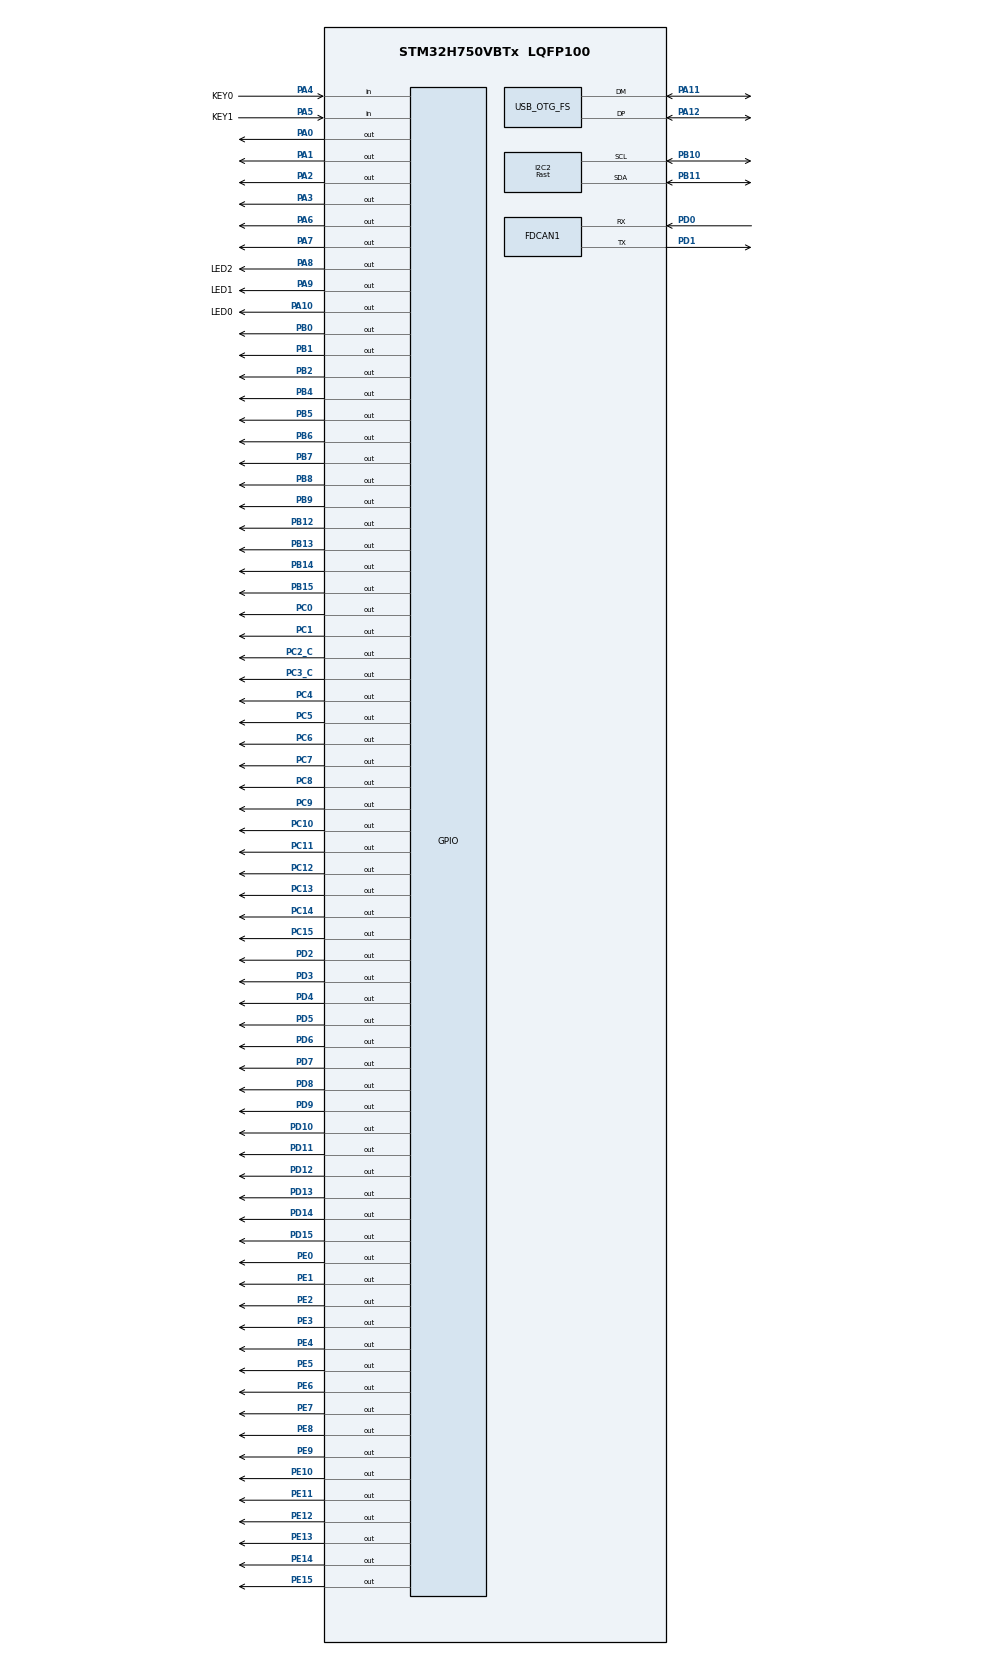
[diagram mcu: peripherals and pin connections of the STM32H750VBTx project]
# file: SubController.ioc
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ADC3.Channel-0\#ChannelRegularConversion=ADC_CHANNEL_TEMPSENSOR
ADC3.Channel-1\#ChannelRegularConversion=ADC_CHANNEL_VREFINT
ADC3.NbrOfConversion=2
ADC3.NbrOfConversionFlag=1
ADC3.OffsetNumber-0\#ChannelRegularConversion=ADC_OFFSET_NONE
ADC3.OffsetNumber-1\#ChannelRegularConversion=ADC_OFFSET_NONE
ADC3.OffsetSignedSaturation-0\#ChannelRegularConversion=DISABLE
ADC3.OffsetSignedSaturation-1\#ChannelRegularConversion=DISABLE
ADC3.Rank-0\#ChannelRegularConversion=1
ADC3.Rank-1\#ChannelRegularConversion=2
ADC3.SamplingTime-0\#ChannelRegularConversion=ADC_SAMPLETIME_810CYCLES_5
ADC3.SamplingTime-1\#ChannelRegularConversion=ADC_SAMPLETIME_810CYCLES_5
CORTEX_M7.BaseAddress_S-Cortex_Memory_Protection_Unit_Region1_Settings_S=0x2400000
CORTEX_M7.CPU_DCache=Disabled
CORTEX_M7.CPU_ICache=Disabled
CORTEX_M7.Enable_S-Cortex_Memory_Protection_Unit_Region1_Settings_S=MPU_REGION_ENABLE
CORTEX_M7.IsCacheable_S-Cortex_Memory_Protection_Unit_Region1_Settings_S=MPU_ACCESS_CACHEABLE
CORTEX_M7.IsShareable_S-Cortex_Memory_Protection_Unit_Region1_Settings_S=MPU_ACCESS_SHAREABLE
CORTEX_M7.MPU_Control=__NULL
CORTEX_M7.Size_S-Cortex_Memory_Protection_Unit_Region1_Settings_S=MPU_REGION_SIZE_512KB
CORTEX_M7.default_mode_Activation=0
Dma.MEMTOMEM.0.Direction=DMA_MEMORY_TO_MEMORY
Dma.MEMTOMEM.0.EventEnable=DISABLE
Dma.MEMTOMEM.0.FIFOMode=DMA_FIFOMODE_ENABLE
Dma.MEMTOMEM.0.FIFOThreshold=DMA_FIFO_THRESHOLD_HALFFULL
Dma.MEMTOMEM.0.Instance=DMA1_Stream0
Dma.MEMTOMEM.0.MemBurst=DMA_MBURST_SINGLE
Dma.MEMTOMEM.0.MemDataAlignment=DMA_MDATAALIGN_HALFWORD
Dma.MEMTOMEM.0.MemInc=DMA_MINC_DISABLE
Dma.MEMTOMEM.0.Mode=DMA_NORMAL
Dma.MEMTOMEM.0.PeriphBurst=DMA_PBURST_SINGLE
Dma.MEMTOMEM.0.PeriphDataAlignment=DMA_PDATAALIGN_HALFWORD
Dma.MEMTOMEM.0.PeriphInc=DMA_PINC_ENABLE
Dma.MEMTOMEM.0.Polarity=HAL_DMAMUX_REQ_GEN_RISING
Dma.MEMTOMEM.0.Priority=DMA_PRIORITY_HIGH
Dma.MEMTOMEM.0.RequestNumber=1
Dma.MEMTOMEM.0.SignalID=NONE
Dma.MEMTOMEM.0.SyncEnable=DISABLE
Dma.MEMTOMEM.0.SyncPolarity=HAL_DMAMUX_SYNC_NO_EVENT
Dma.MEMTOMEM.0.SyncRequestNumber=1
Dma.MEMTOMEM.0.SyncSignalID=NONE
Dma.MEMTOMEM.1.Direction=DMA_MEMORY_TO_MEMORY
Dma.MEMTOMEM.1.EventEnable=DISABLE
Dma.MEMTOMEM.1.FIFOMode=DMA_FIFOMODE_ENABLE
Dma.MEMTOMEM.1.FIFOThreshold=DMA_FIFO_THRESHOLD_HALFFULL
Dma.MEMTOMEM.1.Instance=DMA1_Stream1
Dma.MEMTOMEM.1.MemBurst=DMA_MBURST_SINGLE
Dma.MEMTOMEM.1.MemDataAlignment=DMA_MDATAALIGN_HALFWORD
Dma.MEMTOMEM.1.MemInc=DMA_MINC_DISABLE
Dma.MEMTOMEM.1.Mode=DMA_NORMAL
Dma.MEMTOMEM.1.PeriphBurst=DMA_PBURST_SINGLE
Dma.MEMTOMEM.1.PeriphDataAlignment=DMA_PDATAALIGN_HALFWORD
Dma.MEMTOMEM.1.PeriphInc=DMA_PINC_ENABLE
Dma.MEMTOMEM.1.Polarity=HAL_DMAMUX_REQ_GEN_RISING
Dma.MEMTOMEM.1.Priority=DMA_PRIORITY_HIGH
Dma.MEMTOMEM.1.RequestNumber=1
Dma.MEMTOMEM.1.SignalID=NONE
Dma.MEMTOMEM.1.SyncEnable=DISABLE
Dma.MEMTOMEM.1.SyncPolarity=HAL_DMAMUX_SYNC_NO_EVENT
Dma.MEMTOMEM.1.SyncRequestNumber=1
Dma.MEMTOMEM.1.SyncSignalID=NONE
Dma.MEMTOMEM.2.Direction=DMA_MEMORY_TO_MEMORY
Dma.MEMTOMEM.2.EventEnable=DISABLE
Dma.MEMTOMEM.2.FIFOMode=DMA_FIFOMODE_ENABLE
Dma.MEMTOMEM.2.FIFOThreshold=DMA_FIFO_THRESHOLD_HALFFULL
Dma.MEMTOMEM.2.Instance=DMA1_Stream2
Dma.MEMTOMEM.2.MemBurst=DMA_MBURST_SINGLE
Dma.MEMTOMEM.2.MemDataAlignment=DMA_MDATAALIGN_HALFWORD
Dma.MEMTOMEM.2.MemInc=DMA_MINC_DISABLE
Dma.MEMTOMEM.2.Mode=DMA_NORMAL
Dma.MEMTOMEM.2.PeriphBurst=DMA_PBURST_SINGLE
Dma.MEMTOMEM.2.PeriphDataAlignment=DMA_PDATAALIGN_HALFWORD
Dma.MEMTOMEM.2.PeriphInc=DMA_PINC_ENABLE
Dma.MEMTOMEM.2.Polarity=HAL_DMAMUX_REQ_GEN_RISING
Dma.MEMTOMEM.2.Priority=DMA_PRIORITY_HIGH
Dma.MEMTOMEM.2.RequestNumber=1
Dma.MEMTOMEM.2.SignalID=NONE
Dma.MEMTOMEM.2.SyncEnable=DISABLE
Dma.MEMTOMEM.2.SyncPolarity=HAL_DMAMUX_SYNC_NO_EVENT
Dma.MEMTOMEM.2.SyncRequestNumber=1
Dma.MEMTOMEM.2.SyncSignalID=NONE
Dma.MEMTOMEM.3.Direction=DMA_MEMORY_TO_MEMORY
Dma.MEMTOMEM.3.EventEnable=DISABLE
Dma.MEMTOMEM.3.FIFOMode=DMA_FIFOMODE_ENABLE
Dma.MEMTOMEM.3.FIFOThreshold=DMA_FIFO_THRESHOLD_HALFFULL
Dma.MEMTOMEM.3.Instance=DMA2_Stream0
Dma.MEMTOMEM.3.MemBurst=DMA_MBURST_SINGLE
Dma.MEMTOMEM.3.MemDataAlignment=DMA_MDATAALIGN_HALFWORD
Dma.MEMTOMEM.3.MemInc=DMA_MINC_DISABLE
Dma.MEMTOMEM.3.Mode=DMA_NORMAL
Dma.MEMTOMEM.3.PeriphBurst=DMA_PBURST_SINGLE
Dma.MEMTOMEM.3.PeriphDataAlignment=DMA_PDATAALIGN_HALFWORD
Dma.MEMTOMEM.3.PeriphInc=DMA_PINC_ENABLE
Dma.MEMTOMEM.3.Polarity=HAL_DMAMUX_REQ_GEN_RISING
Dma.MEMTOMEM.3.Priority=DMA_PRIORITY_HIGH
Dma.MEMTOMEM.3.RequestNumber=1
Dma.MEMTOMEM.3.SignalID=NONE
Dma.MEMTOMEM.3.SyncEnable=DISABLE
Dma.MEMTOMEM.3.SyncPolarity=HAL_DMAMUX_SYNC_NO_EVENT
Dma.MEMTOMEM.3.SyncRequestNumber=1
Dma.MEMTOMEM.3.SyncSignalID=NONE
Dma.MEMTOMEM.4.Direction=DMA_MEMORY_TO_MEMORY
Dma.MEMTOMEM.4.EventEnable=DISABLE
Dma.MEMTOMEM.4.FIFOMode=DMA_FIFOMODE_ENABLE
Dma.MEMTOMEM.4.FIFOThreshold=DMA_FIFO_THRESHOLD_HALFFULL
Dma.MEMTOMEM.4.Instance=DMA2_Stream1
Dma.MEMTOMEM.4.MemBurst=DMA_MBURST_SINGLE
Dma.MEMTOMEM.4.MemDataAlignment=DMA_MDATAALIGN_HALFWORD
Dma.MEMTOMEM.4.MemInc=DMA_MINC_DISABLE
Dma.MEMTOMEM.4.Mode=DMA_NORMAL
Dma.MEMTOMEM.4.PeriphBurst=DMA_PBURST_SINGLE
Dma.MEMTOMEM.4.PeriphDataAlignment=DMA_PDATAALIGN_HALFWORD
Dma.MEMTOMEM.4.PeriphInc=DMA_PINC_ENABLE
Dma.MEMTOMEM.4.Polarity=HAL_DMAMUX_REQ_GEN_RISING
Dma.MEMTOMEM.4.Priority=DMA_PRIORITY_HIGH
Dma.MEMTOMEM.4.RequestNumber=1
Dma.MEMTOMEM.4.SignalID=NONE
Dma.MEMTOMEM.4.SyncEnable=DISABLE
Dma.MEMTOMEM.4.SyncPolarity=HAL_DMAMUX_SYNC_NO_EVENT
Dma.MEMTOMEM.4.SyncRequestNumber=1
Dma.MEMTOMEM.4.SyncSignalID=NONE
Dma.MEMTOMEM.5.Direction=DMA_MEMORY_TO_MEMORY
Dma.MEMTOMEM.5.EventEnable=DISABLE
Dma.MEMTOMEM.5.FIFOMode=DMA_FIFOMODE_ENABLE
Dma.MEMTOMEM.5.FIFOThreshold=DMA_FIFO_THRESHOLD_HALFFULL
Dma.MEMTOMEM.5.Instance=DMA2_Stream3
Dma.MEMTOMEM.5.MemBurst=DMA_MBURST_SINGLE
Dma.MEMTOMEM.5.MemDataAlignment=DMA_MDATAALIGN_HALFWORD
Dma.MEMTOMEM.5.MemInc=DMA_MINC_DISABLE
Dma.MEMTOMEM.5.Mode=DMA_NORMAL
Dma.MEMTOMEM.5.PeriphBurst=DMA_PBURST_SINGLE
Dma.MEMTOMEM.5.PeriphDataAlignment=DMA_PDATAALIGN_HALFWORD
Dma.MEMTOMEM.5.PeriphInc=DMA_PINC_ENABLE
Dma.MEMTOMEM.5.Polarity=HAL_DMAMUX_REQ_GEN_RISING
Dma.MEMTOMEM.5.Priority=DMA_PRIORITY_HIGH
Dma.MEMTOMEM.5.RequestNumber=1
Dma.MEMTOMEM.5.SignalID=NONE
Dma.MEMTOMEM.5.SyncEnable=DISABLE
Dma.MEMTOMEM.5.SyncPolarity=HAL_DMAMUX_SYNC_NO_EVENT
Dma.MEMTOMEM.5.SyncRequestNumber=1
Dma.MEMTOMEM.5.SyncSignalID=NONE
Dma.Request0=MEMTOMEM
Dma.Request1=MEMTOMEM
Dma.Request2=MEMTOMEM
Dma.Request3=MEMTOMEM
Dma.Request4=MEMTOMEM
Dma.Request5=MEMTOMEM
FDCAN1.CalculateBaudRateNominal=312500
FDCAN1.CalculateTimeBitNominal=3200
FDCAN1.CalculateTimeQuantumNominal=640.0
I2C2.I2C_Speed_Mode=I2C_Fast
I2C2.Timing=0x009034B6
Mcu.Family=STM32H7
Mcu.Name=STM32H750VBTx
Mcu.Package=LQFP100
NVIC.OTG_FS_IRQn=true\:0\:0\:false\:false\:true\:false\:true\:true
NVIC.PriorityGroup=NVIC_PRIORITYGROUP_4
NVIC.TIM1_UP_IRQn=true\:0\:0\:false\:false\:true\:true\:true\:true
PA0.GPIO_Speed=GPIO_SPEED_FREQ_VERY_HIGH
PA0.Signal=GPIO_Output
PA1.GPIO_Speed=GPIO_SPEED_FREQ_VERY_HIGH
PA1.Signal=GPIO_Output
PA10.GPIO_Label=LED0
PA10.Signal=GPIO_Output
PA11.Mode=Device_Only
PA11.Signal=USB_OTG_FS_DM
PA12.Mode=Device_Only
PA12.Signal=USB_OTG_FS_DP
PA13\ (JTMS/SWDIO).Mode=JTAG_4_pins
PA13\ (JTMS/SWDIO).Signal=DEBUG_JTMS-SWDIO
PA14\ (JTCK/SWCLK).Mode=JTAG_4_pins
PA14\ (JTCK/SWCLK).Signal=DEBUG_JTCK-SWCLK
PA15\ (JTDI).Mode=JTAG_4_pins
PA15\ (JTDI).Signal=DEBUG_JTDI
PA2.GPIO_Speed=GPIO_SPEED_FREQ_VERY_HIGH
PA2.Signal=GPIO_Output
PA3.GPIO_Speed=GPIO_SPEED_FREQ_VERY_HIGH
PA3.Signal=GPIO_Output
PA4.GPIO_Label=KEY0
PA4.Signal=GPIO_Input
PA5.GPIO_Label=KEY1
PA5.Signal=GPIO_Input
PA6.GPIO_Speed=GPIO_SPEED_FREQ_VERY_HIGH
PA6.Signal=GPIO_Output
PA7.GPIO_Speed=GPIO_SPEED_FREQ_VERY_HIGH
PA7.Signal=GPIO_Output
PA8.GPIO_Label=LED2
PA8.Signal=GPIO_Output
PA9.GPIO_Label=LED1
PA9.Signal=GPIO_Output
PB0.GPIO_Speed=GPIO_SPEED_FREQ_VERY_HIGH
PB0.Signal=GPIO_Output
PB1.GPIO_Speed=GPIO_SPEED_FREQ_VERY_HIGH
PB1.Signal=GPIO_Output
PB10.Mode=I2C
PB10.Signal=I2C2_SCL
PB11.Mode=I2C
PB11.Signal=I2C2_SDA
PB12.GPIO_Speed=GPIO_SPEED_FREQ_VERY_HIGH
PB12.Signal=GPIO_Output
PB13.GPIO_Speed=GPIO_SPEED_FREQ_VERY_HIGH
PB13.Signal=GPIO_Output
PB14.GPIO_Speed=GPIO_SPEED_FREQ_VERY_HIGH
PB14.Signal=GPIO_Output
PB15.GPIO_Speed=GPIO_SPEED_FREQ_VERY_HIGH
PB15.Signal=GPIO_Output
PB2.GPIO_Speed=GPIO_SPEED_FREQ_VERY_HIGH
PB2.Signal=GPIO_Output
PB3\ (JTDO/TRACESWO).Mode=JTAG_4_pins
PB3\ (JTDO/TRACESWO).Signal=DEBUG_JTDO-SWO
PB4\ (NJTRST).GPIO_Speed=GPIO_SPEED_FREQ_VERY_HIGH
PB4\ (NJTRST).Signal=GPIO_Output
PB5.GPIO_Speed=GPIO_SPEED_FREQ_VERY_HIGH
PB5.Signal=GPIO_Output
PB6.GPIO_Speed=GPIO_SPEED_FREQ_VERY_HIGH
PB6.Signal=GPIO_Output
PB7.GPIO_Speed=GPIO_SPEED_FREQ_VERY_HIGH
PB7.Signal=GPIO_Output
PB8.GPIO_Speed=GPIO_SPEED_FREQ_VERY_HIGH
PB8.Signal=GPIO_Output
PB9.GPIO_Speed=GPIO_SPEED_FREQ_VERY_HIGH
PB9.Signal=GPIO_Output
PC0.GPIO_Speed=GPIO_SPEED_FREQ_VERY_HIGH
PC0.Signal=GPIO_Output
PC1.GPIO_Speed=GPIO_SPEED_FREQ_VERY_HIGH
PC1.Signal=GPIO_Output
PC10.GPIO_Speed=GPIO_SPEED_FREQ_VERY_HIGH
PC10.Signal=GPIO_Output
PC11.GPIO_Speed=GPIO_SPEED_FREQ_VERY_HIGH
PC11.Signal=GPIO_Output
PC12.GPIO_Speed=GPIO_SPEED_FREQ_VERY_HIGH
PC12.Signal=GPIO_Output
PC13.GPIO_Speed=GPIO_SPEED_FREQ_LOW
PC13.Signal=GPIO_Output
PC14-OSC32_IN\ (OSC32_IN).GPIO_Speed=GPIO_SPEED_FREQ_LOW
PC14-OSC32_IN\ (OSC32_IN).Signal=GPIO_Output
PC15-OSC32_OUT\ (OSC32_OUT).GPIO_Speed=GPIO_SPEED_FREQ_LOW
PC15-OSC32_OUT\ (OSC32_OUT).Signal=GPIO_Output
PC2_C.GPIO_Speed=GPIO_SPEED_FREQ_VERY_HIGH
PC2_C.Signal=GPIO_Output
PC3_C.GPIO_Speed=GPIO_SPEED_FREQ_VERY_HIGH
PC3_C.Signal=GPIO_Output
PC4.GPIO_Speed=GPIO_SPEED_FREQ_VERY_HIGH
PC4.Signal=GPIO_Output
PC5.GPIO_Speed=GPIO_SPEED_FREQ_VERY_HIGH
PC5.Signal=GPIO_Output
PC6.GPIO_Speed=GPIO_SPEED_FREQ_VERY_HIGH
PC6.Signal=GPIO_Output
PC7.GPIO_Speed=GPIO_SPEED_FREQ_VERY_HIGH
PC7.Signal=GPIO_Output
PC8.GPIO_Speed=GPIO_SPEED_FREQ_VERY_HIGH
PC8.Signal=GPIO_Output
PC9.GPIO_Speed=GPIO_SPEED_FREQ_VERY_HIGH
PC9.Signal=GPIO_Output
PD0.Mode=FDCAN_Activate
PD0.Signal=FDCAN1_RX
PD1.Mode=FDCAN_Activate
PD1.Signal=FDCAN1_TX
PD10.GPIO_Speed=GPIO_SPEED_FREQ_VERY_HIGH
PD10.Signal=GPIO_Output
PD11.GPIO_Speed=GPIO_SPEED_FREQ_VERY_HIGH
PD11.Signal=GPIO_Output
PD12.GPIO_Speed=GPIO_SPEED_FREQ_VERY_HIGH
PD12.Signal=GPIO_Output
PD13.GPIO_Speed=GPIO_SPEED_FREQ_VERY_HIGH
PD13.Signal=GPIO_Output
PD14.GPIO_Speed=GPIO_SPEED_FREQ_VERY_HIGH
PD14.Signal=GPIO_Output
PD15.GPIO_Speed=GPIO_SPEED_FREQ_VERY_HIGH
PD15.Signal=GPIO_Output
PD2.GPIO_Speed=GPIO_SPEED_FREQ_VERY_HIGH
PD2.Signal=GPIO_Output
PD3.GPIO_Speed=GPIO_SPEED_FREQ_VERY_HIGH
PD3.Signal=GPIO_Output
PD4.GPIO_Speed=GPIO_SPEED_FREQ_VERY_HIGH
PD4.Signal=GPIO_Output
PD5.GPIO_Speed=GPIO_SPEED_FREQ_VERY_HIGH
PD5.Signal=GPIO_Output
PD6.GPIO_Speed=GPIO_SPEED_FREQ_VERY_HIGH
PD6.Signal=GPIO_Output
PD7.GPIO_Speed=GPIO_SPEED_FREQ_VERY_HIGH
PD7.Signal=GPIO_Output
PD8.GPIO_Speed=GPIO_SPEED_FREQ_VERY_HIGH
PD8.Signal=GPIO_Output
PD9.GPIO_Speed=GPIO_SPEED_FREQ_VERY_HIGH
PD9.Signal=GPIO_Output
PE0.GPIO_Speed=GPIO_SPEED_FREQ_VERY_HIGH
PE0.Signal=GPIO_Output
PE1.GPIO_Speed=GPIO_SPEED_FREQ_VERY_HIGH
PE1.Signal=GPIO_Output
PE10.GPIO_Speed=GPIO_SPEED_FREQ_VERY_HIGH
PE10.Signal=GPIO_Output
PE11.GPIO_Speed=GPIO_SPEED_FREQ_VERY_HIGH
PE11.Signal=GPIO_Output
PE12.GPIO_Speed=GPIO_SPEED_FREQ_VERY_HIGH
PE12.Signal=GPIO_Output
PE13.GPIO_Speed=GPIO_SPEED_FREQ_VERY_HIGH
PE13.Signal=GPIO_Output
PE14.GPIO_Speed=GPIO_SPEED_FREQ_VERY_HIGH
PE14.Signal=GPIO_Output
PE15.GPIO_Speed=GPIO_SPEED_FREQ_VERY_HIGH
PE15.Signal=GPIO_Output
PE2.GPIO_Speed=GPIO_SPEED_FREQ_VERY_HIGH
PE2.Signal=GPIO_Output
PE3.GPIO_Speed=GPIO_SPEED_FREQ_VERY_HIGH
PE3.Signal=GPIO_Output
PE4.GPIO_Speed=GPIO_SPEED_FREQ_VERY_HIGH
PE4.Signal=GPIO_Output
PE5.GPIO_Speed=GPIO_SPEED_FREQ_VERY_HIGH
PE5.Signal=GPIO_Output
PE6.GPIO_Speed=GPIO_SPEED_FREQ_VERY_HIGH
PE6.Signal=GPIO_Output
PE7.GPIO_Speed=GPIO_SPEED_FREQ_VERY_HIGH
PE7.Signal=GPIO_Output
PE8.GPIO_Speed=GPIO_SPEED_FREQ_VERY_HIGH
PE8.Signal=GPIO_Output
PE9.GPIO_Speed=GPIO_SPEED_FREQ_VERY_HIGH
PE9.Signal=GPIO_Output
PH0-OSC_IN\ (PH0).Mode=HSE-External-Oscillator
PH0-OSC_IN\ (PH0).Signal=RCC_OSC_IN
PH1-OSC_OUT\ (PH1).Mode=HSE-External-Oscillator
PH1-OSC_OUT\ (PH1).Signal=RCC_OSC_OUT
ProjectManager.HeapSize=0x200
ProjectManager.StackSize=0x400
ProjectManager.TargetToolchain=Makefile
RCC.ADCCLockSelection=RCC_ADCCLKSOURCE_CLKP
RCC.ADCFreq_Value=64000000
RCC.APB1Freq_Value=100000000
RCC.APB2Freq_Value=100000000
RCC.APB3Freq_Value=100000000
RCC.APB4Freq_Value=100000000
RCC.CortexFreq_Value=400000000
RCC.D1PPRE=RCC_APB3_DIV2
RCC.D2PPRE1=RCC_APB1_DIV2
RCC.D2PPRE2=RCC_APB2_DIV2
RCC.D3PPRE=RCC_APB4_DIV2
RCC.DIVM1=2
RCC.DIVM2=10
RCC.DIVN1=64
RCC.DIVN2=100
RCC.DIVQ1=13
RCC.FDCANCLockSelection=RCC_FDCANCLKSOURCE_HSE
RCC.HCLKFreq_Value=200000000
RCC.HPRE=RCC_HCLK_DIV2
RCC.HSE_VALUE=25000000
RCC.PLLSourceVirtual=RCC_PLLSOURCE_HSE
RCC.SYSCLKFreq_VALUE=400000000
RCC.SYSCLKSource=RCC_SYSCLKSOURCE_PLLCLK
RCC.USBCLockSelection=RCC_USBCLKSOURCE_HSI48
RCC.USBFreq_Value=48000000
TIM1.AutoReloadPreload=TIM_AUTORELOAD_PRELOAD_ENABLE
TIM1.Period=1000
TIM1.Prescaler=1000
USB_DEVICE.CLASS_NAME_FS=CDC
USB_DEVICE.USBD_LPM_ENABLED-CDC_FS=0
USB_DEVICE.VirtualMode-CDC_FS=Cdc
USB_DEVICE.VirtualModeFS=Cdc_FS
USB_OTG_FS.VirtualMode=Device_Only
VP_ADC3_TempSens_Input.Mode=IN-TempSens
VP_ADC3_Vref_Input.Mode=IN-Vrefint
VP_TIM1_VS_ClockSourceINT.Mode=Internal
VP_USB_DEVICE_VS_USB_DEVICE_CDC_FS.Mode=CDC_FS
board=custom

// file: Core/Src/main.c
/* USER CODE BEGIN Header */
/**
 ******************************************************************************
 * @file           : main.c
 * @brief          : Main program body
 ******************************************************************************
 * @attention
 *
 * Copyright (c) 2024 STMicroelectronics.
 * All rights reserved.
 *
 * This software is licensed under terms that can be found in the LICENSE file
 * in the root directory of this software component.
 * If no LICENSE file comes with this software, it is provided AS-IS.
 *
 ******************************************************************************
 */
/* USER CODE END Header */
#include "main.h"
#include "usb_device.h"

/* USER CODE BEGIN Includes */

#include "dma_manager.h"
#include "transducer.h"
#include "simulation.h"
#include "calibration.h"
#include "custom_math.h"
#include "utiles.h"
#include "communication.h"

/* USER CODE END Includes */

ADC_HandleTypeDef hadc3;

FDCAN_HandleTypeDef hfdcan1;

I2C_HandleTypeDef hi2c2;

TIM_HandleTypeDef htim1;

DMA_HandleTypeDef hdma_memtomem_dma1_stream0;
DMA_HandleTypeDef hdma_memtomem_dma1_stream1;
DMA_HandleTypeDef hdma_memtomem_dma1_stream2;
DMA_HandleTypeDef hdma_memtomem_dma2_stream0;
DMA_HandleTypeDef hdma_memtomem_dma2_stream1;
DMA_HandleTypeDef hdma_memtomem_dma2_stream3;
/* USER CODE BEGIN PV */

DMA_HandleTypeDef hdma_memtomem_dma1_stream0;
DMA_HandleTypeDef hdma_memtomem_dma1_stream1;
DMA_HandleTypeDef hdma_memtomem_dma1_stream2;
DMA_HandleTypeDef hdma_memtomem_dma2_stream0;
DMA_HandleTypeDef hdma_memtomem_dma2_stream1;
DMA_HandleTypeDef hdma_memtomem_dma2_stream3;

/* USER CODE END PV */

void SystemClock_Config(void);
void PeriphCommonClock_Config(void);
static void MX_GPIO_Init(void);
static void MX_DMA_Init(void);
static void MX_I2C2_Init(void);
static void MX_FDCAN1_Init(void);
static void MX_TIM1_Init(void);
static void MX_ADC3_Init(void);

int main(void)
{

  /* MCU Configuration--------------------------------------------------------*/

  /* Reset of all peripherals, Initializes the Flash interface and the Systick. */
  HAL_Init();

  /* USER CODE BEGIN Init */

  static uint32_t loop_count = 0;
  static uint32_t last_check_tick = 0;

  /* USER CODE END Init */

  /* Configure the system clock */
  SystemClock_Config();

/* Configure the peripherals common clocks */
  PeriphCommonClock_Config();

  /* Initialize all configured peripherals */
  MX_GPIO_Init();
  MX_DMA_Init();
  MX_I2C2_Init();
  MX_USB_DEVICE_Init();
  MX_FDCAN1_Init();
  MX_TIM1_Init();
  MX_ADC3_Init();
  /* USER CODE BEGIN 2 */

  Comm_Init();
  Init_DWT();
  Transducer_Init();
  DMA_Init();

  /* USER CODE END 2 */

  /* Infinite loop */
  /* USER CODE BEGIN WHILE */

  while (1)
  {
    loop_count++;
    if (HAL_GetTick() - last_check_tick >= 1000)
    {
      System_Loop_Freq = (float)loop_count;
      loop_count = 0;
      last_check_tick = HAL_GetTick();
    }

    sysTickDelta = SysTick->VAL;

    LED_Indicate_Blink();

    // Calibration Mode Switch
    Switch_Calibration_Mode();

    // Simulation Mode Switch
    Switch_Simulation_Mode();

    Apply_Vibration();

    /* USER CODE END WHILE */

  }
}

void SystemClock_Config(void)
{
  RCC_OscInitTypeDef RCC_OscInitStruct = {0};
  RCC_ClkInitTypeDef RCC_ClkInitStruct = {0};

  /** Supply configuration update enable
  */
  HAL_PWREx_ConfigSupply(PWR_LDO_SUPPLY);

  /** Configure the main internal regulator output voltage
  */
  __HAL_PWR_VOLTAGESCALING_CONFIG(PWR_REGULATOR_VOLTAGE_SCALE1);

  while(!__HAL_PWR_GET_FLAG(PWR_FLAG_VOSRDY)) {}

  /** Initializes the RCC Oscillators according to the specified parameters
  * in the RCC_OscInitTypeDef structure.
  */
  RCC_OscInitStruct.OscillatorType = RCC_OSCILLATORTYPE_HSI48|RCC_OSCILLATORTYPE_HSI
                              |RCC_OSCILLATORTYPE_HSE;
  RCC_OscInitStruct.HSEState = RCC_HSE_ON;
  RCC_OscInitStruct.HSIState = RCC_HSI_DIV1;
  RCC_OscInitStruct.HSICalibrationValue = RCC_HSICALIBRATION_DEFAULT;
  RCC_OscInitStruct.HSI48State = RCC_HSI48_ON;
  RCC_OscInitStruct.PLL.PLLState = RCC_PLL_ON;
  RCC_OscInitStruct.PLL.PLLSource = RCC_PLLSOURCE_HSE;
  RCC_OscInitStruct.PLL.PLLM = 2;
  RCC_OscInitStruct.PLL.PLLN = 64;
  RCC_OscInitStruct.PLL.PLLP = 2;
  RCC_OscInitStruct.PLL.PLLQ = 13;
  RCC_OscInitStruct.PLL.PLLR = 2;
  RCC_OscInitStruct.PLL.PLLRGE = RCC_PLL1VCIRANGE_3;
  RCC_OscInitStruct.PLL.PLLVCOSEL = RCC_PLL1VCOWIDE;
  RCC_OscInitStruct.PLL.PLLFRACN = 0;
  if (HAL_RCC_OscConfig(&RCC_OscInitStruct) != HAL_OK)
  {
    Error_Handler();
  }

  /** Initializes the CPU, AHB and APB buses clocks
  */
  RCC_ClkInitStruct.ClockType = RCC_CLOCKTYPE_HCLK|RCC_CLOCKTYPE_SYSCLK
                              |RCC_CLOCKTYPE_PCLK1|RCC_CLOCKTYPE_PCLK2
                              |RCC_CLOCKTYPE_D3PCLK1|RCC_CLOCKTYPE_D1PCLK1;
  RCC_ClkInitStruct.SYSCLKSource = RCC_SYSCLKSOURCE_PLLCLK;
  RCC_ClkInitStruct.SYSCLKDivider = RCC_SYSCLK_DIV1;
  RCC_ClkInitStruct.AHBCLKDivider = RCC_HCLK_DIV2;
  RCC_ClkInitStruct.APB3CLKDivider = RCC_APB3_DIV2;
  RCC_ClkInitStruct.APB1CLKDivider = RCC_APB1_DIV2;
  RCC_ClkInitStruct.APB2CLKDivider = RCC_APB2_DIV2;
  RCC_ClkInitStruct.APB4CLKDivider = RCC_APB4_DIV2;

  if (HAL_RCC_ClockConfig(&RCC_ClkInitStruct, FLASH_LATENCY_2) != HAL_OK)
  {
    Error_Handler();
  }
}

void PeriphCommonClock_Config(void)
{
  RCC_PeriphCLKInitTypeDef PeriphClkInitStruct = {0};

  /** Initializes the peripherals clock
  */
  PeriphClkInitStruct.PeriphClockSelection = RCC_PERIPHCLK_CKPER;
  PeriphClkInitStruct.CkperClockSelection = RCC_CLKPSOURCE_HSI;
  if (HAL_RCCEx_PeriphCLKConfig(&PeriphClkInitStruct) != HAL_OK)
  {
    Error_Handler();
  }
}

static void MX_ADC3_Init(void)
{

  ADC_ChannelConfTypeDef sConfig = {0};

  /** Common config
  */
  hadc3.Instance = ADC3;
  hadc3.Init.Resolution = ADC_RESOLUTION_16B;
  hadc3.Init.ScanConvMode = ADC_SCAN_ENABLE;
  hadc3.Init.EOCSelection = ADC_EOC_SINGLE_CONV;
  hadc3.Init.LowPowerAutoWait = DISABLE;
  hadc3.Init.ContinuousConvMode = DISABLE;
  hadc3.Init.NbrOfConversion = 2;
  hadc3.Init.DiscontinuousConvMode = DISABLE;
  hadc3.Init.ExternalTrigConv = ADC_SOFTWARE_START;
  hadc3.Init.ExternalTrigConvEdge = ADC_EXTERNALTRIGCONVEDGE_NONE;
  hadc3.Init.ConversionDataManagement = ADC_CONVERSIONDATA_DR;
  hadc3.Init.Overrun = ADC_OVR_DATA_PRESERVED;
  hadc3.Init.LeftBitShift = ADC_LEFTBITSHIFT_NONE;
  hadc3.Init.OversamplingMode = DISABLE;
  if (HAL_ADC_Init(&hadc3) != HAL_OK)
  {
    Error_Handler();
  }

  /** Configure Regular Channel
  */
  sConfig.Channel = ADC_CHANNEL_TEMPSENSOR;
  sConfig.Rank = ADC_REGULAR_RANK_1;
  sConfig.SamplingTime = ADC_SAMPLETIME_810CYCLES_5;
  sConfig.SingleDiff = ADC_SINGLE_ENDED;
  sConfig.OffsetNumber = ADC_OFFSET_NONE;
  sConfig.Offset = 0;
  sConfig.OffsetSignedSaturation = DISABLE;
  if (HAL_ADC_ConfigChannel(&hadc3, &sConfig) != HAL_OK)
  {
    Error_Handler();
  }

  /** Configure Regular Channel
  */
  sConfig.Channel = ADC_CHANNEL_VREFINT;
  sConfig.Rank = ADC_REGULAR_RANK_2;
  if (HAL_ADC_ConfigChannel(&hadc3, &sConfig) != HAL_OK)
  {
    Error_Handler();
  }

}

static void MX_FDCAN1_Init(void)
{

  hfdcan1.Instance = FDCAN1;
  hfdcan1.Init.FrameFormat = FDCAN_FRAME_CLASSIC;
  hfdcan1.Init.Mode = FDCAN_MODE_NORMAL;
  hfdcan1.Init.AutoRetransmission = DISABLE;
  hfdcan1.Init.TransmitPause = DISABLE;
  hfdcan1.Init.ProtocolException = DISABLE;
  hfdcan1.Init.NominalPrescaler = 16;
  hfdcan1.Init.NominalSyncJumpWidth = 1;
  hfdcan1.Init.NominalTimeSeg1 = 2;
  hfdcan1.Init.NominalTimeSeg2 = 2;
  hfdcan1.Init.DataPrescaler = 1;
  hfdcan1.Init.DataSyncJumpWidth = 1;
  hfdcan1.Init.DataTimeSeg1 = 1;
  hfdcan1.Init.DataTimeSeg2 = 1;
  hfdcan1.Init.MessageRAMOffset = 0;
  hfdcan1.Init.StdFiltersNbr = 0;
  hfdcan1.Init.ExtFiltersNbr = 0;
  hfdcan1.Init.RxFifo0ElmtsNbr = 0;
  hfdcan1.Init.RxFifo0ElmtSize = FDCAN_DATA_BYTES_8;
  hfdcan1.Init.RxFifo1ElmtsNbr = 0;
  hfdcan1.Init.RxFifo1ElmtSize = FDCAN_DATA_BYTES_8;
  hfdcan1.Init.RxBuffersNbr = 0;
  hfdcan1.Init.RxBufferSize = FDCAN_DATA_BYTES_8;
  hfdcan1.Init.TxEventsNbr = 0;
  hfdcan1.Init.TxBuffersNbr = 0;
  hfdcan1.Init.TxFifoQueueElmtsNbr = 0;
  hfdcan1.Init.TxFifoQueueMode = FDCAN_TX_FIFO_OPERATION;
  hfdcan1.Init.TxElmtSize = FDCAN_DATA_BYTES_8;
  if (HAL_FDCAN_Init(&hfdcan1) != HAL_OK)
  {
    Error_Handler();
  }

}

static void MX_I2C2_Init(void)
{

  hi2c2.Instance = I2C2;
  hi2c2.Init.Timing = 0x009034B6;
  hi2c2.Init.OwnAddress1 = 0;
  hi2c2.Init.AddressingMode = I2C_ADDRESSINGMODE_7BIT;
  hi2c2.Init.DualAddressMode = I2C_DUALADDRESS_DISABLE;
  hi2c2.Init.OwnAddress2 = 0;
  hi2c2.Init.OwnAddress2Masks = I2C_OA2_NOMASK;
  hi2c2.Init.GeneralCallMode = I2C_GENERALCALL_DISABLE;
  hi2c2.Init.NoStretchMode = I2C_NOSTRETCH_DISABLE;
  if (HAL_I2C_Init(&hi2c2) != HAL_OK)
  {
    Error_Handler();
  }

  /** Configure Analogue filter
  */
  if (HAL_I2CEx_ConfigAnalogFilter(&hi2c2, I2C_ANALOGFILTER_ENABLE) != HAL_OK)
  {
    Error_Handler();
  }

  /** Configure Digital filter
  */
  if (HAL_I2CEx_ConfigDigitalFilter(&hi2c2, 0) != HAL_OK)
  {
    Error_Handler();
  }

}

static void MX_TIM1_Init(void)
{

  TIM_ClockConfigTypeDef sClockSourceConfig = {0};
  TIM_MasterConfigTypeDef sMasterConfig = {0};

  htim1.Instance = TIM1;
  htim1.Init.Prescaler = 1000;
  htim1.Init.CounterMode = TIM_COUNTERMODE_UP;
  htim1.Init.Period = 1000;
  htim1.Init.ClockDivision = TIM_CLOCKDIVISION_DIV1;
  htim1.Init.RepetitionCounter = 0;
  htim1.Init.AutoReloadPreload = TIM_AUTORELOAD_PRELOAD_ENABLE;
  if (HAL_TIM_Base_Init(&htim1) != HAL_OK)
  {
    Error_Handler();
  }
  sClockSourceConfig.ClockSource = TIM_CLOCKSOURCE_INTERNAL;
  if (HAL_TIM_ConfigClockSource(&htim1, &sClockSourceConfig) != HAL_OK)
  {
    Error_Handler();
  }
  sMasterConfig.MasterOutputTrigger = TIM_TRGO_RESET;
  sMasterConfig.MasterOutputTrigger2 = TIM_TRGO2_RESET;
  sMasterConfig.MasterSlaveMode = TIM_MASTERSLAVEMODE_DISABLE;
  if (HAL_TIMEx_MasterConfigSynchronization(&htim1, &sMasterConfig) != HAL_OK)
  {
    Error_Handler();
  }
  /* USER CODE BEGIN TIM1_Init 2 */
  __HAL_FREEZE_TIM1_DBGMCU();
  /* USER CODE END TIM1_Init 2 */

}

static void MX_DMA_Init(void)
{

  /* DMA controller clock enable */
  __HAL_RCC_DMA1_CLK_ENABLE();
  __HAL_RCC_DMA2_CLK_ENABLE();

  /* Configure DMA request hdma_memtomem_dma1_stream0 on DMA1_Stream0 */
  hdma_memtomem_dma1_stream0.Instance = DMA1_Stream0;
  hdma_memtomem_dma1_stream0.Init.Request = DMA_REQUEST_MEM2MEM;
  hdma_memtomem_dma1_stream0.Init.Direction = DMA_MEMORY_TO_MEMORY;
  hdma_memtomem_dma1_stream0.Init.PeriphInc = DMA_PINC_ENABLE;
  hdma_memtomem_dma1_stream0.Init.MemInc = DMA_MINC_DISABLE;
  hdma_memtomem_dma1_stream0.Init.PeriphDataAlignment = DMA_PDATAALIGN_HALFWORD;
  hdma_memtomem_dma1_stream0.Init.MemDataAlignment = DMA_MDATAALIGN_HALFWORD;
  hdma_memtomem_dma1_stream0.Init.Mode = DMA_CIRCULAR;
  hdma_memtomem_dma1_stream0.Init.Priority = DMA_PRIORITY_HIGH;
  hdma_memtomem_dma1_stream0.Init.FIFOMode = DMA_FIFOMODE_DISABLE;
  hdma_memtomem_dma1_stream0.Init.FIFOThreshold = DMA_FIFO_THRESHOLD_HALFFULL;
  hdma_memtomem_dma1_stream0.Init.MemBurst = DMA_MBURST_SINGLE;
  hdma_memtomem_dma1_stream0.Init.PeriphBurst = DMA_PBURST_SINGLE;
  if (HAL_DMA_Init(&hdma_memtomem_dma1_stream0) != HAL_OK)
  {
    Error_Handler( );
  }

  /* Configure DMA request hdma_memtomem_dma1_stream1 on DMA1_Stream1 */
  hdma_memtomem_dma1_stream1.Instance = DMA1_Stream1;
  hdma_memtomem_dma1_stream1.Init.Request = DMA_REQUEST_MEM2MEM;
  hdma_memtomem_dma1_stream1.Init.Direction = DMA_MEMORY_TO_MEMORY;
  hdma_memtomem_dma1_stream1.Init.PeriphInc = DMA_PINC_ENABLE;
  hdma_memtomem_dma1_stream1.Init.MemInc = DMA_MINC_DISABLE;
  hdma_memtomem_dma1_stream1.Init.PeriphDataAlignment = DMA_PDATAALIGN_HALFWORD;
  hdma_memtomem_dma1_stream1.Init.MemDataAlignment = DMA_MDATAALIGN_HALFWORD;
  hdma_memtomem_dma1_stream1.Init.Mode = DMA_CIRCULAR;
  hdma_memtomem_dma1_stream1.Init.Priority = DMA_PRIORITY_HIGH;
  hdma_memtomem_dma1_stream1.Init.FIFOMode = DMA_FIFOMODE_DISABLE;
  hdma_memtomem_dma1_stream1.Init.FIFOThreshold = DMA_FIFO_THRESHOLD_HALFFULL;
  hdma_memtomem_dma1_stream1.Init.MemBurst = DMA_MBURST_SINGLE;
  hdma_memtomem_dma1_stream1.Init.PeriphBurst = DMA_PBURST_SINGLE;
  if (HAL_DMA_Init(&hdma_memtomem_dma1_stream1) != HAL_OK)
  {
    Error_Handler( );
  }

  /* Configure DMA request hdma_memtomem_dma1_stream2 on DMA1_Stream2 */
  hdma_memtomem_dma1_stream2.Instance = DMA1_Stream2;
  hdma_memtomem_dma1_stream2.Init.Request = DMA_REQUEST_MEM2MEM;
  hdma_memtomem_dma1_stream2.Init.Direction = DMA_MEMORY_TO_MEMORY;
  hdma_memtomem_dma1_stream2.Init.PeriphInc = DMA_PINC_ENABLE;
  hdma_memtomem_dma1_stream2.Init.MemInc = DMA_MINC_DISABLE;
  hdma_memtomem_dma1_stream2.Init.PeriphDataAlignment = DMA_PDATAALIGN_HALFWORD;
  hdma_memtomem_dma1_stream2.Init.MemDataAlignment = DMA_MDATAALIGN_HALFWORD;
  hdma_memtomem_dma1_stream2.Init.Mode = DMA_CIRCULAR;
  hdma_memtomem_dma1_stream2.Init.Priority = DMA_PRIORITY_HIGH;
  hdma_memtomem_dma1_stream2.Init.FIFOMode = DMA_FIFOMODE_DISABLE;
  hdma_memtomem_dma1_stream2.Init.FIFOThreshold = DMA_FIFO_THRESHOLD_HALFFULL;
  hdma_memtomem_dma1_stream2.Init.MemBurst = DMA_MBURST_SINGLE;
  hdma_memtomem_dma1_stream2.Init.PeriphBurst = DMA_PBURST_SINGLE;
  if (HAL_DMA_Init(&hdma_memtomem_dma1_stream2) != HAL_OK)
  {
    Error_Handler( );
  }

  /* Configure DMA request hdma_memtomem_dma2_stream0 on DMA2_Stream0 */
  hdma_memtomem_dma2_stream0.Instance = DMA2_Stream0;
  hdma_memtomem_dma2_stream0.Init.Request = DMA_REQUEST_MEM2MEM;
  hdma_memtomem_dma2_stream0.Init.Direction = DMA_MEMORY_TO_MEMORY;
  hdma_memtomem_dma2_stream0.Init.PeriphInc = DMA_PINC_ENABLE;
  hdma_memtomem_dma2_stream0.Init.MemInc = DMA_MINC_DISABLE;
  hdma_memtomem_dma2_stream0.Init.PeriphDataAlignment = DMA_PDATAALIGN_HALFWORD;
  hdma_memtomem_dma2_stream0.Init.MemDataAlignment = DMA_MDATAALIGN_HALFWORD;
  hdma_memtomem_dma2_stream0.Init.Mode = DMA_CIRCULAR;
  hdma_memtomem_dma2_stream0.Init.Priority = DMA_PRIORITY_HIGH;
  hdma_memtomem_dma2_stream0.Init.FIFOMode = DMA_FIFOMODE_DISABLE;
  hdma_memtomem_dma2_stream0.Init.FIFOThreshold = DMA_FIFO_THRESHOLD_HALFFULL;
  hdma_memtomem_dma2_stream0.Init.MemBurst = DMA_MBURST_SINGLE;
  hdma_memtomem_dma2_stream0.Init.PeriphBurst = DMA_PBURST_SINGLE;
  if (HAL_DMA_Init(&hdma_memtomem_dma2_stream0) != HAL_OK)
  {
    Error_Handler( );
  }

  /* Configure DMA request hdma_memtomem_dma2_stream1 on DMA2_Stream1 */
  hdma_memtomem_dma2_stream1.Instance = DMA2_Stream1;
  hdma_memtomem_dma2_stream1.Init.Request = DMA_REQUEST_MEM2MEM;
  hdma_memtomem_dma2_stream1.Init.Direction = DMA_MEMORY_TO_MEMORY;
  hdma_memtomem_dma2_stream1.Init.PeriphInc = DMA_PINC_ENABLE;
  hdma_memtomem_dma2_stream1.Init.MemInc = DMA_MINC_DISABLE;
  hdma_memtomem_dma2_stream1.Init.PeriphDataAlignment = DMA_PDATAALIGN_HALFWORD;
  hdma_memtomem_dma2_stream1.Init.MemDataAlignment = DMA_MDATAALIGN_HALFWORD;
  hdma_memtomem_dma2_stream1.Init.Mode = DMA_CIRCULAR;
  hdma_memtomem_dma2_stream1.Init.Priority = DMA_PRIORITY_HIGH;
  hdma_memtomem_dma2_stream1.Init.FIFOMode = DMA_FIFOMODE_DISABLE;
  hdma_memtomem_dma2_stream1.Init.FIFOThreshold = DMA_FIFO_THRESHOLD_HALFFULL;
  hdma_memtomem_dma2_stream1.Init.MemBurst = DMA_MBURST_SINGLE;
  hdma_memtomem_dma2_stream1.Init.PeriphBurst = DMA_PBURST_SINGLE;
  if (HAL_DMA_Init(&hdma_memtomem_dma2_stream1) != HAL_OK)
  {
    Error_Handler( );
  }

  /* Configure DMA request hdma_memtomem_dma2_stream3 on DMA2_Stream3 */
  hdma_memtomem_dma2_stream3.Instance = DMA2_Stream3;
  hdma_memtomem_dma2_stream3.Init.Request = DMA_REQUEST_MEM2MEM;
  hdma_memtomem_dma2_stream3.Init.Direction = DMA_MEMORY_TO_MEMORY;
  hdma_memtomem_dma2_stream3.Init.PeriphInc = DMA_PINC_ENABLE;
  hdma_memtomem_dma2_stream3.Init.MemInc = DMA_MINC_DISABLE;
  hdma_memtomem_dma2_stream3.Init.PeriphDataAlignment = DMA_PDATAALIGN_HALFWORD;
  hdma_memtomem_dma2_stream3.Init.MemDataAlignment = DMA_MDATAALIGN_HALFWORD;
  hdma_memtomem_dma2_stream3.Init.Mode = DMA_CIRCULAR;
  hdma_memtomem_dma2_stream3.Init.Priority = DMA_PRIORITY_HIGH;
  hdma_memtomem_dma2_stream3.Init.FIFOMode = DMA_FIFOMODE_DISABLE;
  hdma_memtomem_dma2_stream3.Init.FIFOThreshold = DMA_FIFO_THRESHOLD_HALFFULL;
  hdma_memtomem_dma2_stream3.Init.MemBurst = DMA_MBURST_SINGLE;
  hdma_memtomem_dma2_stream3.Init.PeriphBurst = DMA_PBURST_SINGLE;
  if (HAL_DMA_Init(&hdma_memtomem_dma2_stream3) != HAL_OK)
  {
    Error_Handler( );
  }

}

static void MX_GPIO_Init(void)
{
  GPIO_InitTypeDef GPIO_InitStruct = {0};

  /* GPIO Ports Clock Enable */
  __HAL_RCC_GPIOE_CLK_ENABLE();
  __HAL_RCC_GPIOC_CLK_ENABLE();
  __HAL_RCC_GPIOH_CLK_ENABLE();
  __HAL_RCC_GPIOA_CLK_ENABLE();
  __HAL_RCC_GPIOB_CLK_ENABLE();
  __HAL_RCC_GPIOD_CLK_ENABLE();

  /*Configure GPIO pin Output Level */
  HAL_GPIO_WritePin(GPIOE, GPIO_PIN_2|GPIO_PIN_3|GPIO_PIN_4|GPIO_PIN_5
                          |GPIO_PIN_6|GPIO_PIN_7|GPIO_PIN_8|GPIO_PIN_9
                          |GPIO_PIN_10|GPIO_PIN_11|GPIO_PIN_12|GPIO_PIN_13
                          |GPIO_PIN_14|GPIO_PIN_15|GPIO_PIN_0|GPIO_PIN_1, GPIO_PIN_RESET);

  /*Configure GPIO pin Output Level */
  HAL_GPIO_WritePin(GPIOC, GPIO_PIN_13|GPIO_PIN_14|GPIO_PIN_15|GPIO_PIN_0
                          |GPIO_PIN_1|GPIO_PIN_2|GPIO_PIN_3|GPIO_PIN_4
                          |GPIO_PIN_5|GPIO_PIN_6|GPIO_PIN_7|GPIO_PIN_8
                          |GPIO_PIN_9|GPIO_PIN_10|GPIO_PIN_11|GPIO_PIN_12, GPIO_PIN_RESET);

  /*Configure GPIO pin Output Level */
  HAL_GPIO_WritePin(GPIOA, GPIO_PIN_0|GPIO_PIN_1|GPIO_PIN_2|GPIO_PIN_3
                          |GPIO_PIN_6|GPIO_PIN_7|LED2_Pin|LED1_Pin
                          |LED0_Pin, GPIO_PIN_RESET);

  /*Configure GPIO pin Output Level */
  HAL_GPIO_WritePin(GPIOB, GPIO_PIN_0|GPIO_PIN_1|GPIO_PIN_2|GPIO_PIN_12
                          |GPIO_PIN_13|GPIO_PIN_14|GPIO_PIN_15|GPIO_PIN_4
                          |GPIO_PIN_5|GPIO_PIN_6|GPIO_PIN_7|GPIO_PIN_8
                          |GPIO_PIN_9, GPIO_PIN_RESET);

  /*Configure GPIO pin Output Level */
  HAL_GPIO_WritePin(GPIOD, GPIO_PIN_8|GPIO_PIN_9|GPIO_PIN_10|GPIO_PIN_11
                          |GPIO_PIN_12|GPIO_PIN_13|GPIO_PIN_14|GPIO_PIN_15
                          |GPIO_PIN_2|GPIO_PIN_3|GPIO_PIN_4|GPIO_PIN_5
                          |GPIO_PIN_6|GPIO_PIN_7, GPIO_PIN_RESET);

  /*Configure GPIO pins : PE2 PE3 PE4 PE5
                           PE6 PE7 PE8 PE9
                           PE10 PE11 PE12 PE13
                           PE14 PE15 PE0 PE1 */
  GPIO_InitStruct.Pin = GPIO_PIN_2|GPIO_PIN_3|GPIO_PIN_4|GPIO_PIN_5
                          |GPIO_PIN_6|GPIO_PIN_7|GPIO_PIN_8|GPIO_PIN_9
                          |GPIO_PIN_10|GPIO_PIN_11|GPIO_PIN_12|GPIO_PIN_13
                          |GPIO_PIN_14|GPIO_PIN_15|GPIO_PIN_0|GPIO_PIN_1;
  GPIO_InitStruct.Mode = GPIO_MODE_OUTPUT_PP;
  GPIO_InitStruct.Pull = GPIO_NOPULL;
  GPIO_InitStruct.Speed = GPIO_SPEED_FREQ_VERY_HIGH;
  HAL_GPIO_Init(GPIOE, &GPIO_InitStruct);

  /*Configure GPIO pins : PC13 PC14 PC15 */
  GPIO_InitStruct.Pin = GPIO_PIN_13|GPIO_PIN_14|GPIO_PIN_15;
  GPIO_InitStruct.Mode = GPIO_MODE_OUTPUT_PP;
  GPIO_InitStruct.Pull = GPIO_NOPULL;
  GPIO_InitStruct.Speed = GPIO_SPEED_FREQ_LOW;
  HAL_GPIO_Init(GPIOC, &GPIO_InitStruct);

  /*Configure GPIO pins : PC0 PC1 PC2 PC3
                           PC4 PC5 PC6 PC7
                           PC8 PC9 PC10 PC11
                           PC12 */
  GPIO_InitStruct.Pin = GPIO_PIN_0|GPIO_PIN_1|GPIO_PIN_2|GPIO_PIN_3
                          |GPIO_PIN_4|GPIO_PIN_5|GPIO_PIN_6|GPIO_PIN_7
                          |GPIO_PIN_8|GPIO_PIN_9|GPIO_PIN_10|GPIO_PIN_11
                          |GPIO_PIN_12;
  GPIO_InitStruct.Mode = GPIO_MODE_OUTPUT_PP;
  GPIO_InitStruct.Pull = GPIO_NOPULL;
  GPIO_InitStruct.Speed = GPIO_SPEED_FREQ_VERY_HIGH;
  HAL_GPIO_Init(GPIOC, &GPIO_InitStruct);

  /*Configure GPIO pins : PA0 PA1 PA2 PA3
                           PA6 PA7 */
  GPIO_InitStruct.Pin = GPIO_PIN_0|GPIO_PIN_1|GPIO_PIN_2|GPIO_PIN_3
                          |GPIO_PIN_6|GPIO_PIN_7;
  GPIO_InitStruct.Mode = GPIO_MODE_OUTPUT_PP;
  GPIO_InitStruct.Pull = GPIO_NOPULL;
  GPIO_InitStruct.Speed = GPIO_SPEED_FREQ_VERY_HIGH;
  HAL_GPIO_Init(GPIOA, &GPIO_InitStruct);

  /*Configure GPIO pins : KEY0_Pin KEY1_Pin */
  GPIO_InitStruct.Pin = KEY0_Pin|KEY1_Pin;
  GPIO_InitStruct.Mode = GPIO_MODE_INPUT;
  GPIO_InitStruct.Pull = GPIO_NOPULL;
  HAL_GPIO_Init(GPIOA, &GPIO_InitStruct);

  /*Configure GPIO pins : PB0 PB1 PB2 PB12
                           PB13 PB14 PB15 PB4
                           PB5 PB6 PB7 PB8
                           PB9 */
  GPIO_InitStruct.Pin = GPIO_PIN_0|GPIO_PIN_1|GPIO_PIN_2|GPIO_PIN_12
                          |GPIO_PIN_13|GPIO_PIN_14|GPIO_PIN_15|GPIO_PIN_4
                          |GPIO_PIN_5|GPIO_PIN_6|GPIO_PIN_7|GPIO_PIN_8
                          |GPIO_PIN_9;
  GPIO_InitStruct.Mode = GPIO_MODE_OUTPUT_PP;
  GPIO_InitStruct.Pull = GPIO_NOPULL;
  GPIO_InitStruct.Speed = GPIO_SPEED_FREQ_VERY_HIGH;
  HAL_GPIO_Init(GPIOB, &GPIO_InitStruct);

  /*Configure GPIO pins : PD8 PD9 PD10 PD11
                           PD12 PD13 PD14 PD15
                           PD2 PD3 PD4 PD5
                           PD6 PD7 */
  GPIO_InitStruct.Pin = GPIO_PIN_8|GPIO_PIN_9|GPIO_PIN_10|GPIO_PIN_11
                          |GPIO_PIN_12|GPIO_PIN_13|GPIO_PIN_14|GPIO_PIN_15
                          |GPIO_PIN_2|GPIO_PIN_3|GPIO_PIN_4|GPIO_PIN_5
                          |GPIO_PIN_6|GPIO_PIN_7;
  GPIO_InitStruct.Mode = GPIO_MODE_OUTPUT_PP;
  GPIO_InitStruct.Pull = GPIO_NOPULL;
  GPIO_InitStruct.Speed = GPIO_SPEED_FREQ_VERY_HIGH;
  HAL_GPIO_Init(GPIOD, &GPIO_InitStruct);

  /*Configure GPIO pins : LED2_Pin LED1_Pin LED0_Pin */
  GPIO_InitStruct.Pin = LED2_Pin|LED1_Pin|LED0_Pin;
  GPIO_InitStruct.Mode = GPIO_MODE_OUTPUT_PP;
  GPIO_InitStruct.Pull = GPIO_NOPULL;
  GPIO_InitStruct.Speed = GPIO_SPEED_FREQ_LOW;
  HAL_GPIO_Init(GPIOA, &GPIO_InitStruct);

}

void Error_Handler(void)
{
  /* USER CODE BEGIN Error_Handler_Debug */
  /* User can add his own implementation to report the HAL error return state */
  __disable_irq();

  for (size_t i = 0; i < 64; ++i)
  {
    free(&TransducerArray[i]);
  }

  while (1)
  {
    Toggle_LED_State(LED0_Pin);
    Toggle_LED_State(LED1_Pin);
    Toggle_LED_State(LED2_Pin);
    HAL_Delay(500);
  }
  /* USER CODE END Error_Handler_Debug */
}
